# AST1080 register map
File version: 1.0
CPU: CM4 r0p1, little endian, MPU, FPU, 4 interrupt priority bits, 256 interrupts
Registers are 32-bit, read-write, reset 0x0 unless marked. A register's access mark holds for its fields unless they carry their own. Offsets are from the block's base; [hi:lo] are bit positions.

## jtag
Base 0x74C01000
0x00 JTAG000 — Data Port register
  [31:0] DataPortReg
0x04 JTAG004 — Data Port register
  [31:0] DataPortReg1
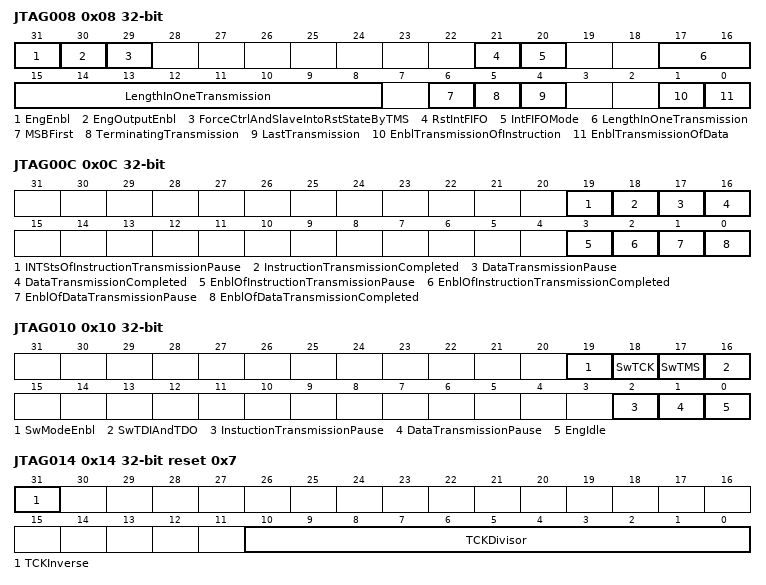
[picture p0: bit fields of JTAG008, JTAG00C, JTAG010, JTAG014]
0x08 JTAG008 — Engine control
  [31] EngEnbl — Engine enable.
  [30] EngOutputEnbl — Engine output enable.
    1=Output_Enable; 0=Output_Disable
  [29] ForceCtrlAndSlaveIntoRstStateByTMS — Force controller and slave into Reset state by TMS.
  [21] RstIntFIFO — Reset Internal FIFO
  [20] IntFIFOMode ro — Internal FIFO mode
    0=CPU_Mode; 1=Controller_Mode
  [17:8] LengthInOneTransmission
  [6] MSBFirst
    1=MSB_First; 0=LSB_First
  [5] TerminatingTransmission
    1=Terminate; 0=Normal_Operation
  [4] LastTransmission
    1=Last_Transmission; 0=More_Data_Waited
  [1] EnblTransmissionOfInstruction — Enable transmission of instruction.
  [0] EnblTransmissionOfData — Enable transmission of data.
0x0C JTAG00C — Interrupt status and enable
  [19] INTStsOfInstructionTransmissionPause — Interrupt status of instruction transmission pause.
    0=No_Interrupt_Pending; 1=Interrupt_Pending
  [18] InstructionTransmissionCompleted
    0=No_Interrupt_Pending; 1=Interrupt_Pending
  [17] DataTransmissionPause
    0=No_Interrupt_Pending; 1=Interrupt_Pending
  [16] DataTransmissionCompleted
    0=No_Interrupt_Pending; 1=Interrupt_Pending
  [3] EnblOfInstructionTransmissionPause — Enable of Instruction transmission pause.
    0=Disable_Interrupt; 1=Enable_Interrupt
  [2] EnblOfInstructionTransmissionCompleted — Enable of Instruction transmission completed.
    0=Disable_Interrupt; 1=Enable_Interrupt
  [1] EnblOfDataTransmissionPause — Enable of Data transmission pause.
    0=Disable_Interrupt; 1=Enable_Interrupt
  [0] EnblOfDataTransmissionCompleted — Enable of Data transmission completed.
    0=Disable_Interrupt; 1=Enable_Interrupt
0x10 JTAG010 — Software mode and status
  [19] SwModeEnbl — Software mode enable.
  [18] SwTCK — Software TCK.
  [17] SwTMS — Software TMS.
  [16] SwTDIAndTDO — Software TDI and TDO.
  [2] InstuctionTransmissionPause ro
  [1] DataTransmissionPause ro
  [0] EngIdle ro — Engine idle.
0x14 JTAG014 reset 0x7 — TCK Control
  [31] TCKInverse
    1=Inverse_TCK; 0=Not_Inverse_TCK
  [10:0] TCKDivisor
0x18 JTAG018 reset 0x80000000 — Engine Control 1
  [31] CtrlOfTRSTn — Control of TRSTn.
    1=TRSTn_Is_High; 0=TRSTn_Is_Low
0x20 JTAG020 — Data Port register
  [31:0] ShiftData3100
0x24 JTAG024 — Data Port register
  [31:0] ShiftData31001 — Shift Data [31:00]
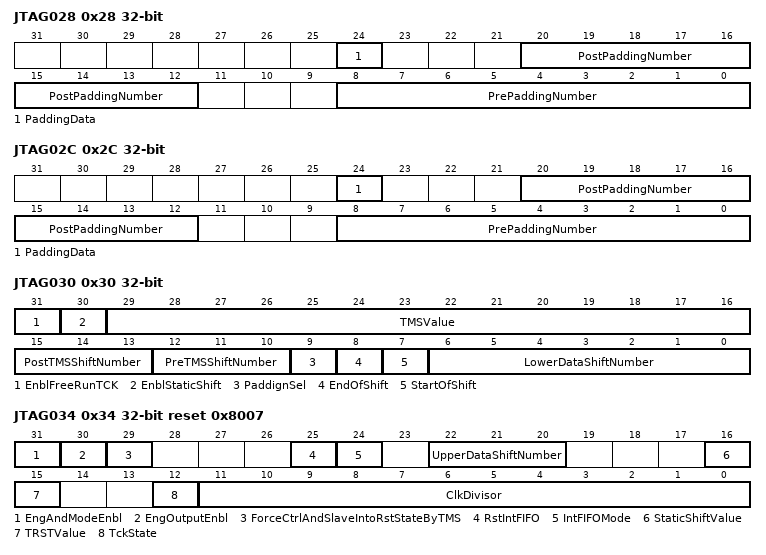
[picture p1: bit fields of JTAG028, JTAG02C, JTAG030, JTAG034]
0x28 JTAG028 — Padding control 0
  [24] PaddingData, [20:12] PostPaddingNumber, [8:0] PrePaddingNumber
0x2C JTAG02C — Padding control 1
  [24] PaddingData, [20:12] PostPaddingNumber, [8:0] PrePaddingNumber
0x30 JTAG030 — Shift control
  [31] EnblFreeRunTCK — Enable Free Run TCK
    1=TCK_Is_Free_Running; 0=TCK_Toggles_Only_When_Necessary
  [30] EnblStaticShift — Enable Static Shift
  [29:16] TMSValue
  [15:13] PostTMSShiftNumber
  [12:10] PreTMSShiftNumber
  [9] PaddignSel — Paddign selection
    0=Use_JTAG28_For_Padding_Setting; 1=Use_JTAG2C_For_Padding_Setting
  [8] EndOfShift
  [7] StartOfShift
  [6:0] LowerDataShiftNumber
0x34 JTAG034 reset 0x8007 (reset mask 0xE3718FFF) — Global control
  [31] EngAndModeEnbl — Engine and Mode Enable
  [30] EngOutputEnbl — Engine output enable.
    1=Output_Enable; 0=Output_Disable
  [29] ForceCtrlAndSlaveIntoRstStateByTMS — Force controller and slave into Reset state by TMS.
  [25] RstIntFIFO — Reset Internal FIFO
  [24] IntFIFOMode ro — Internal FIFO mode
    0=CPU_Mode; 1=Controller_Mode
  [22:20] UpperDataShiftNumber
  [16] StaticShiftValue
  [15] TRSTValue
  [12] TckState
  [11:0] ClkDivisor — Clock divisor
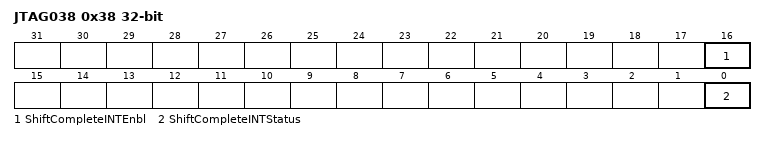
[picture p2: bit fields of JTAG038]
0x38 JTAG038 — Interrupt control
  [16] ShiftCompleteINTEnbl — Shift Complete Interrupt Enable
  [0] ShiftCompleteINTStatus — Shift Complete Interrupt Status
    0=No_Interrupt_Pending; 1=Interrupt_Pending
0x3C JTAG03C — Status
  [0] EngIdle ro — Engine Idle
